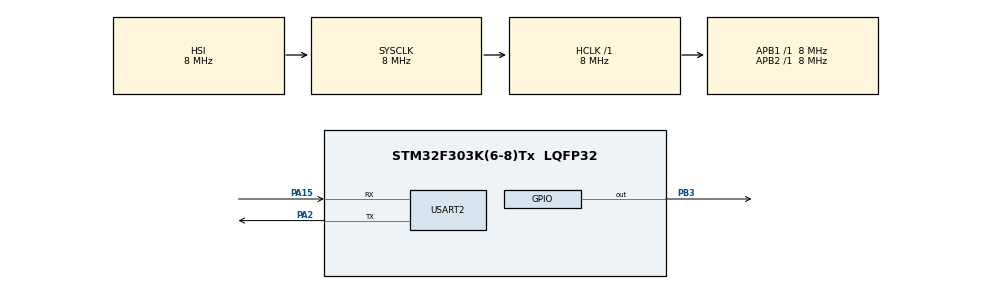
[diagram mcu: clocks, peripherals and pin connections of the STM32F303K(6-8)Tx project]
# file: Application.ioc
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Mcu.Family=STM32F3
Mcu.Name=STM32F303K(6-8)Tx
Mcu.Package=LQFP32
NVIC.PriorityGroup=NVIC_PRIORITYGROUP_4
PA15.Mode=Asynchronous
PA15.Signal=USART2_RX
PA2.Mode=Asynchronous
PA2.Signal=USART2_TX
PB3.Signal=GPIO_Output
ProjectManager.HeapSize=0x200
ProjectManager.StackSize=0x400
ProjectManager.TargetToolchain=STM32CubeIDE
RCC.AHBFreq_Value=8000000
RCC.APB1Freq_Value=8000000
RCC.APB2Freq_Value=8000000
RCC.CortexFreq_Value=8000000
RCC.HSE_VALUE=8000000
RCC.HSI_VALUE=8000000
RCC.SYSCLKFreq_VALUE=8000000
USART2.VirtualMode-Asynchronous=VM_ASYNC
board=custom

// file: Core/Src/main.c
/* USER CODE BEGIN Header */
/**
  ******************************************************************************
  * @file           : main.c
  * @brief          : Main program body
  ******************************************************************************
  * @attention
  *
  * Copyright (c) 2023 STMicroelectronics.
  * All rights reserved.
  *
  * This software is licensed under terms that can be found in the LICENSE file
  * in the root directory of this software component.
  * If no LICENSE file comes with this software, it is provided AS-IS.
  *
  ******************************************************************************
  */
/* USER CODE END Header */
#include "main.h"

/* USER CODE BEGIN Includes */
#include <stdio.h>
/* USER CODE END Includes */

/* USER CODE BEGIN PM */
#define MAJOR 0
#define MINOR 1
/* USER CODE END PM */

UART_HandleTypeDef huart2;

/* USER CODE BEGIN PV */
const uint8_t APPversion[2] = {MAJOR,MINOR};
/* USER CODE END PV */

void SystemClock_Config(void);
static void MX_GPIO_Init(void);
static void MX_USART2_UART_Init(void);

int main(void)
{

  /* MCU Configuration--------------------------------------------------------*/

  /* Reset of all peripherals, Initializes the Flash interface and the Systick. */
  HAL_Init();

  /* Configure the system clock */
  SystemClock_Config();

  /* Initialize all configured peripherals */
  MX_GPIO_Init();
  MX_USART2_UART_Init();
  /* USER CODE BEGIN 2 */
  printf("Starting Application : version = %d,%d\n",APPversion[0],APPversion[1]);

  /* USER CODE END 2 */

  /* Infinite loop */
  /* USER CODE BEGIN WHILE */
  uint8_t i = 0 ;
  while (1)
  {
	  HAL_GPIO_WritePin(GPIOB, GPIO_PIN_3, GPIO_PIN_SET);
	  HAL_Delay(1000);
	  HAL_GPIO_WritePin(GPIOB, GPIO_PIN_3, GPIO_PIN_RESET);
	  HAL_Delay(1000);
	  printf("Loop N = %d",i);
	  i++;
    /* USER CODE END WHILE */

  }
}

void SystemClock_Config(void)
{
  RCC_OscInitTypeDef RCC_OscInitStruct = {0};
  RCC_ClkInitTypeDef RCC_ClkInitStruct = {0};

  /** Initializes the RCC Oscillators according to the specified parameters
  * in the RCC_OscInitTypeDef structure.
  */
  RCC_OscInitStruct.OscillatorType = RCC_OSCILLATORTYPE_HSI;
  RCC_OscInitStruct.HSIState = RCC_HSI_ON;
  RCC_OscInitStruct.HSICalibrationValue = RCC_HSICALIBRATION_DEFAULT;
  RCC_OscInitStruct.PLL.PLLState = RCC_PLL_NONE;
  if (HAL_RCC_OscConfig(&RCC_OscInitStruct) != HAL_OK)
  {
    Error_Handler();
  }

  /** Initializes the CPU, AHB and APB buses clocks
  */
  RCC_ClkInitStruct.ClockType = RCC_CLOCKTYPE_HCLK|RCC_CLOCKTYPE_SYSCLK
                              |RCC_CLOCKTYPE_PCLK1|RCC_CLOCKTYPE_PCLK2;
  RCC_ClkInitStruct.SYSCLKSource = RCC_SYSCLKSOURCE_HSI;
  RCC_ClkInitStruct.AHBCLKDivider = RCC_SYSCLK_DIV1;
  RCC_ClkInitStruct.APB1CLKDivider = RCC_HCLK_DIV1;
  RCC_ClkInitStruct.APB2CLKDivider = RCC_HCLK_DIV1;

  if (HAL_RCC_ClockConfig(&RCC_ClkInitStruct, FLASH_LATENCY_0) != HAL_OK)
  {
    Error_Handler();
  }
}

static void MX_USART2_UART_Init(void)
{

  huart2.Instance = USART2;
  huart2.Init.BaudRate = 9600;
  huart2.Init.WordLength = UART_WORDLENGTH_8B;
  huart2.Init.StopBits = UART_STOPBITS_1;
  huart2.Init.Parity = UART_PARITY_NONE;
  huart2.Init.Mode = UART_MODE_TX_RX;
  huart2.Init.HwFlowCtl = UART_HWCONTROL_NONE;
  huart2.Init.OverSampling = UART_OVERSAMPLING_16;
  huart2.Init.OneBitSampling = UART_ONE_BIT_SAMPLE_DISABLE;
  huart2.AdvancedInit.AdvFeatureInit = UART_ADVFEATURE_NO_INIT;
  if (HAL_UART_Init(&huart2) != HAL_OK)
  {
    Error_Handler();
  }

}

static void MX_GPIO_Init(void)
{
  GPIO_InitTypeDef GPIO_InitStruct = {0};

  /* GPIO Ports Clock Enable */
  __HAL_RCC_GPIOA_CLK_ENABLE();
  __HAL_RCC_GPIOB_CLK_ENABLE();

  /*Configure GPIO pin Output Level */
  HAL_GPIO_WritePin(GPIOB, GPIO_PIN_3, GPIO_PIN_RESET);

  /*Configure GPIO pin : PB3 */
  GPIO_InitStruct.Pin = GPIO_PIN_3;
  GPIO_InitStruct.Mode = GPIO_MODE_OUTPUT_PP;
  GPIO_InitStruct.Pull = GPIO_NOPULL;
  GPIO_InitStruct.Speed = GPIO_SPEED_FREQ_LOW;
  HAL_GPIO_Init(GPIOB, &GPIO_InitStruct);

}

/* USER CODE BEGIN 4 */
#ifdef __GNUC__
int __io_putchar(int ch)
#else
int fputc(int ch, FILE * f)
#endif
{
	HAL_UART_Transmit(&huart2,(uint8_t *) &ch, 1, HAL_MAX_DELAY);
	return ch;
}

/* USER CODE END 4 */

void Error_Handler(void)
{
  __disable_irq();
  while (1)
  {
  }
}
